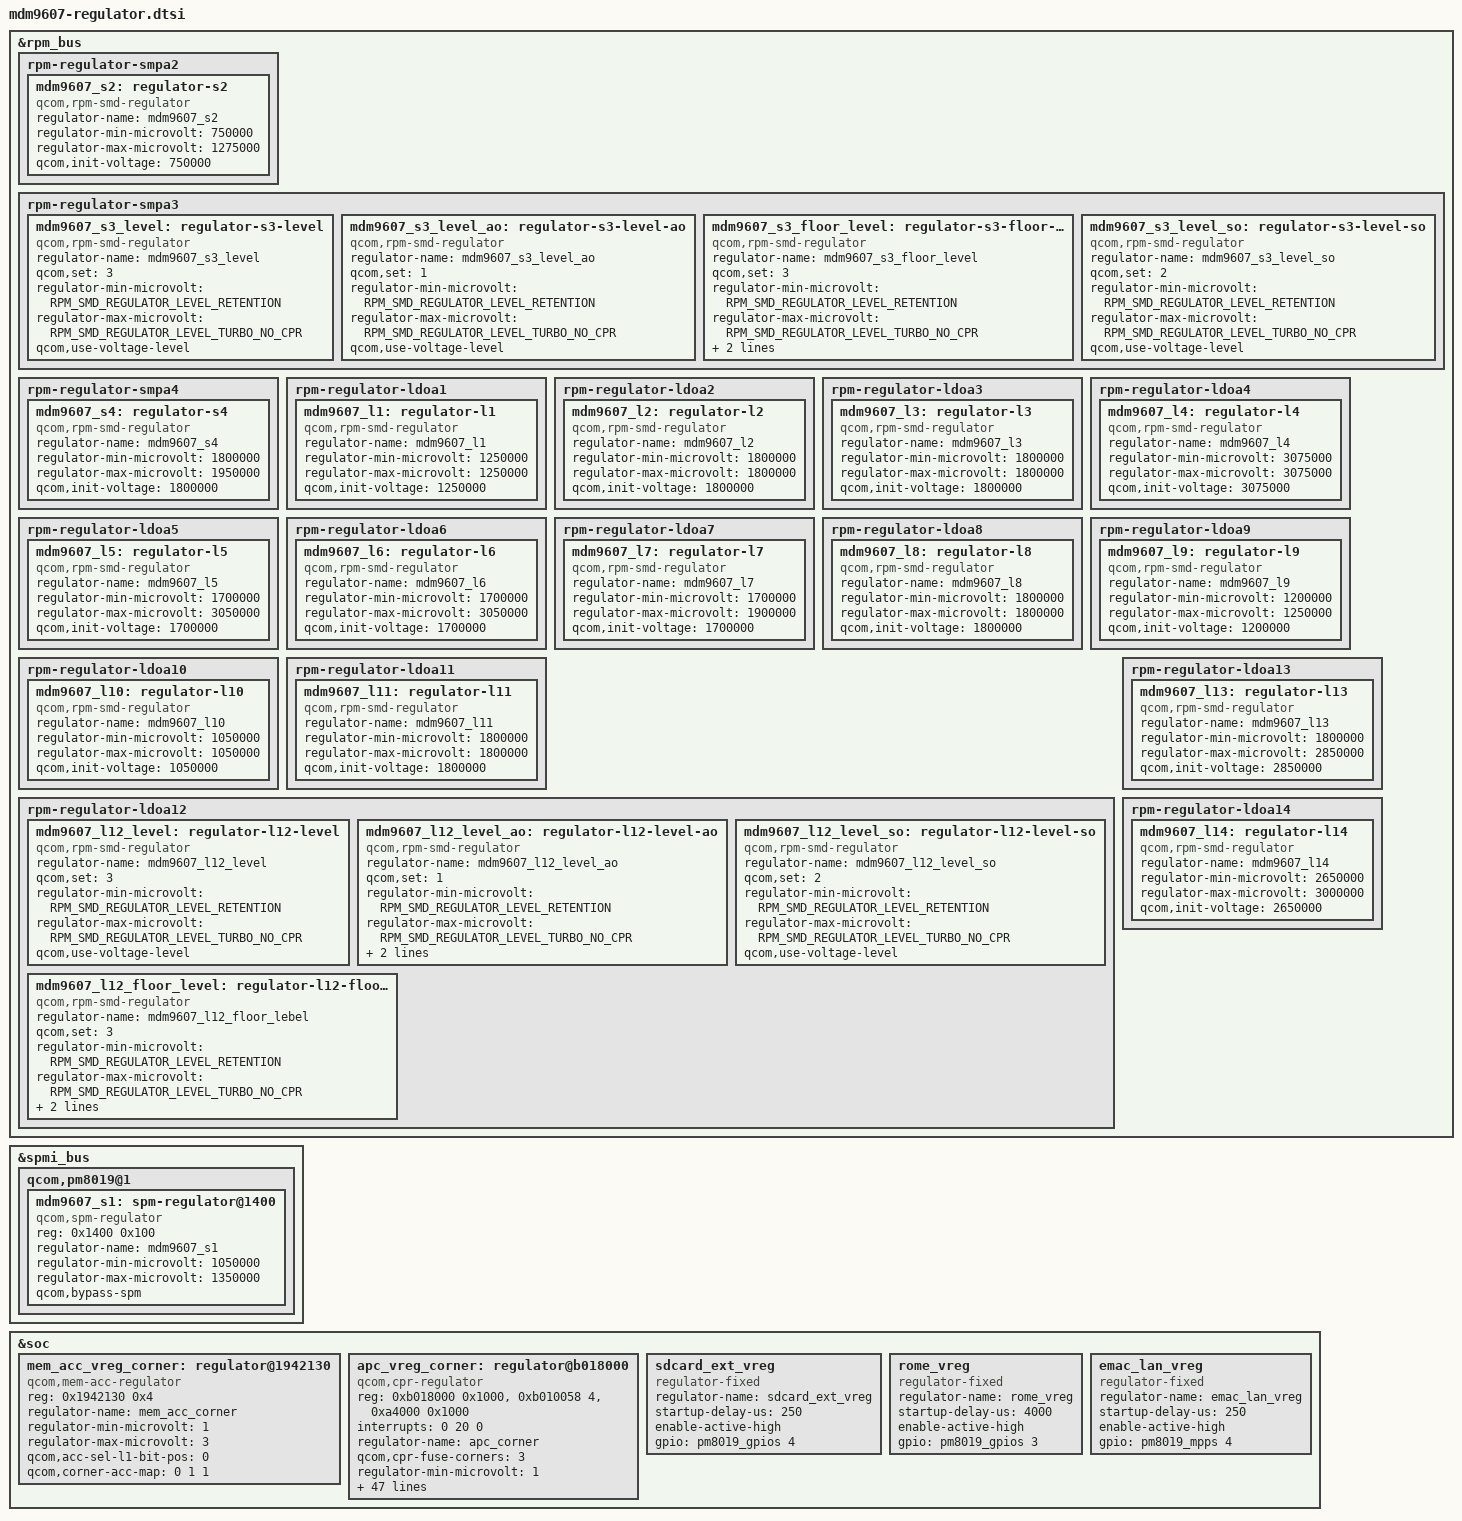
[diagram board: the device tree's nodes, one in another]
/* Copyright (c) 2015-2017, The Linux Foundation. All rights reserved.
 *
 * This program is free software; you can redistribute it and/or modify
 * it under the terms of the GNU General Public License version 2 and
 * only version 2 as published by the Free Software Foundation.
 *
 * This program is distributed in the hope that it will be useful,
 * but WITHOUT ANY WARRANTY; without even the implied warranty of
 * MERCHANTABILITY or FITNESS FOR A PARTICULAR PURPOSE.  See the
 * GNU General Public License for more details.
 */

&rpm_bus {
	rpm-regulator-smpa2 {
		status = "okay";
		mdm9607_s2: regulator-s2 {
			compatible = "qcom,rpm-smd-regulator";
			regulator-name = "mdm9607_s2";
			regulator-min-microvolt = <750000>;
			regulator-max-microvolt = <1275000>;
			qcom,init-voltage = <750000>;
			status = "okay";
		};
	};

	/* CX supply */
	rpm-regulator-smpa3 {
		status = "okay";
		mdm9607_s3_level: regulator-s3-level {
			compatible = "qcom,rpm-smd-regulator";
			regulator-name = "mdm9607_s3_level";
			qcom,set = <3>;
			regulator-min-microvolt =
					<RPM_SMD_REGULATOR_LEVEL_RETENTION>;
			regulator-max-microvolt =
					<RPM_SMD_REGULATOR_LEVEL_TURBO_NO_CPR>;
			qcom,use-voltage-level;
		};

		mdm9607_s3_level_ao: regulator-s3-level-ao {
			compatible = "qcom,rpm-smd-regulator";
			regulator-name = "mdm9607_s3_level_ao";
			qcom,set = <1>;
			regulator-min-microvolt =
					<RPM_SMD_REGULATOR_LEVEL_RETENTION>;
			regulator-max-microvolt =
					<RPM_SMD_REGULATOR_LEVEL_TURBO_NO_CPR>;
			qcom,use-voltage-level;
		};

		mdm9607_s3_floor_level: regulator-s3-floor-level {
			compatible = "qcom,rpm-smd-regulator";
			regulator-name = "mdm9607_s3_floor_level";
			qcom,set = <3>;
			regulator-min-microvolt =
					<RPM_SMD_REGULATOR_LEVEL_RETENTION>;
			regulator-max-microvolt =
					<RPM_SMD_REGULATOR_LEVEL_TURBO_NO_CPR>;
			qcom,use-voltage-floor-level;
			qcom,always-send-voltage;
		};

		mdm9607_s3_level_so: regulator-s3-level-so {
			compatible = "qcom,rpm-smd-regulator";
			regulator-name = "mdm9607_s3_level_so";
			qcom,set = <2>;
			regulator-min-microvolt =
					<RPM_SMD_REGULATOR_LEVEL_RETENTION>;
			regulator-max-microvolt =
					<RPM_SMD_REGULATOR_LEVEL_TURBO_NO_CPR>;
			qcom,use-voltage-level;
		};
	};

	rpm-regulator-smpa4 {
		status = "okay";
		mdm9607_s4: regulator-s4 {
			compatible = "qcom,rpm-smd-regulator";
			regulator-name = "mdm9607_s4";
			regulator-min-microvolt = <1800000>;
			regulator-max-microvolt = <1950000>;
			qcom,init-voltage = <1800000>;
			status = "okay";
		};
	};

	rpm-regulator-ldoa1 {
		status = "okay";
		mdm9607_l1: regulator-l1 {
			compatible = "qcom,rpm-smd-regulator";
			regulator-name = "mdm9607_l1";
			regulator-min-microvolt = <1250000>;
			regulator-max-microvolt = <1250000>;
			qcom,init-voltage = <1250000>;
			status = "okay";
		};
	};

	rpm-regulator-ldoa2 {
		status = "okay";
		mdm9607_l2: regulator-l2 {
			compatible = "qcom,rpm-smd-regulator";
			regulator-name = "mdm9607_l2";
			regulator-min-microvolt = <1800000>;
			regulator-max-microvolt = <1800000>;
			qcom,init-voltage = <1800000>;
			status = "okay";
		};
	};

	rpm-regulator-ldoa3 {
		status = "okay";
		mdm9607_l3: regulator-l3 {
			compatible = "qcom,rpm-smd-regulator";
			regulator-name = "mdm9607_l3";
			regulator-min-microvolt = <1800000>;
			regulator-max-microvolt = <1800000>;
			qcom,init-voltage = <1800000>;
			status = "okay";
		};
	};

	rpm-regulator-ldoa4 {
		status = "okay";
		mdm9607_l4: regulator-l4 {
			compatible = "qcom,rpm-smd-regulator";
			regulator-name = "mdm9607_l4";
			regulator-min-microvolt = <3075000>;
			regulator-max-microvolt = <3075000>;
			qcom,init-voltage = <3075000>;
			status = "okay";
		};
	};

	rpm-regulator-ldoa5 {
		status = "okay";
		mdm9607_l5: regulator-l5 {
			compatible = "qcom,rpm-smd-regulator";
			regulator-name = "mdm9607_l5";
			regulator-min-microvolt = <1700000>;
			regulator-max-microvolt = <3050000>;
			qcom,init-voltage = <1700000>;
			status = "okay";
		};
	};

	rpm-regulator-ldoa6 {
		status = "okay";
		mdm9607_l6: regulator-l6 {
			compatible = "qcom,rpm-smd-regulator";
			regulator-name = "mdm9607_l6";
			regulator-min-microvolt = <1700000>;
			regulator-max-microvolt = <3050000>;
			qcom,init-voltage = <1700000>;
			status = "okay";
		};
	};

	rpm-regulator-ldoa7 {
		status = "okay";
		mdm9607_l7: regulator-l7 {
			compatible = "qcom,rpm-smd-regulator";
			regulator-name = "mdm9607_l7";
			regulator-min-microvolt = <1700000>;
			regulator-max-microvolt = <1900000>;
			qcom,init-voltage = <1700000>;
			status = "okay";
		};
	};

	rpm-regulator-ldoa8 {
		status = "okay";
		mdm9607_l8: regulator-l8 {
			compatible = "qcom,rpm-smd-regulator";
			regulator-name = "mdm9607_l8";
			regulator-min-microvolt = <1800000>;
			regulator-max-microvolt = <1800000>;
			qcom,init-voltage = <1800000>;
			status = "okay";
		};
	};

	rpm-regulator-ldoa9 {
		status = "okay";
		mdm9607_l9: regulator-l9 {
			compatible = "qcom,rpm-smd-regulator";
			regulator-name = "mdm9607_l9";
			regulator-min-microvolt = <1200000>;
			regulator-max-microvolt = <1250000>;
			qcom,init-voltage = <1200000>;
			status = "okay";
		};
	};

	rpm-regulator-ldoa10 {
		status = "okay";
		mdm9607_l10: regulator-l10 {
			compatible = "qcom,rpm-smd-regulator";
			regulator-name = "mdm9607_l10";
			regulator-min-microvolt = <1050000>;
			regulator-max-microvolt = <1050000>;
			qcom,init-voltage = <1050000>;
			status = "okay";
		};
	};

	rpm-regulator-ldoa11 {
		status = "okay";
		mdm9607_l11: regulator-l11 {
			compatible = "qcom,rpm-smd-regulator";
			regulator-name = "mdm9607_l11";
			regulator-min-microvolt = <1800000>;
			regulator-max-microvolt = <1800000>;
			qcom,init-voltage = <1800000>;
			status = "okay";
		};
	};

	/* MX supply */
	rpm-regulator-ldoa12 {
		status = "okay";
		mdm9607_l12_level: regulator-l12-level {
			compatible = "qcom,rpm-smd-regulator";
			regulator-name = "mdm9607_l12_level";
			qcom,set = <3>;
			regulator-min-microvolt =
					<RPM_SMD_REGULATOR_LEVEL_RETENTION>;
			regulator-max-microvolt =
					<RPM_SMD_REGULATOR_LEVEL_TURBO_NO_CPR>;
			qcom,use-voltage-level;
		};

		mdm9607_l12_level_ao: regulator-l12-level-ao {
			compatible = "qcom,rpm-smd-regulator";
			regulator-name = "mdm9607_l12_level_ao";
			qcom,set = <1>;
			regulator-min-microvolt =
					<RPM_SMD_REGULATOR_LEVEL_RETENTION>;
			regulator-max-microvolt =
					<RPM_SMD_REGULATOR_LEVEL_TURBO_NO_CPR>;
			qcom,use-voltage-level;
			qcom,always-send-voltage;
		};

		mdm9607_l12_level_so: regulator-l12-level-so {
			compatible = "qcom,rpm-smd-regulator";
			regulator-name = "mdm9607_l12_level_so";
			qcom,set = <2>;
			regulator-min-microvolt =
					<RPM_SMD_REGULATOR_LEVEL_RETENTION>;
			regulator-max-microvolt =
					<RPM_SMD_REGULATOR_LEVEL_TURBO_NO_CPR>;
			qcom,use-voltage-level;
		};

		mdm9607_l12_floor_level: regulator-l12-floor-level {
			compatible = "qcom,rpm-smd-regulator";
			regulator-name = "mdm9607_l12_floor_lebel";
			qcom,set = <3>;
			regulator-min-microvolt =
					<RPM_SMD_REGULATOR_LEVEL_RETENTION>;
			regulator-max-microvolt =
					<RPM_SMD_REGULATOR_LEVEL_TURBO_NO_CPR>;
			qcom,use-voltage-floor-level;
			qcom,always-send-voltage;
		};
	};

	rpm-regulator-ldoa13 {
		status = "okay";
		mdm9607_l13: regulator-l13 {
			compatible = "qcom,rpm-smd-regulator";
			regulator-name = "mdm9607_l13";
			regulator-min-microvolt = <1800000>;
			regulator-max-microvolt = <2850000>;
			qcom,init-voltage = <2850000>;
			status = "okay";
		};
	};

	rpm-regulator-ldoa14 {
		status = "okay";
		mdm9607_l14: regulator-l14 {
			compatible = "qcom,rpm-smd-regulator";
			regulator-name = "mdm9607_l14";
			regulator-min-microvolt = <2650000>;
			regulator-max-microvolt = <3000000>;
			qcom,init-voltage = <2650000>;
			status = "okay";
		};
	};
};

&spmi_bus {
	qcom,pm8019@1 {
		/* APC supply */
		mdm9607_s1: spm-regulator@1400 {
			compatible = "qcom,spm-regulator";
			reg = <0x1400 0x100>;
			regulator-name = "mdm9607_s1";
			regulator-min-microvolt = <1050000>;
			regulator-max-microvolt = <1350000>;
			qcom,bypass-spm; /* TODO: Remove once SPM is up */
		};
	};
};

&soc {
	mem_acc_vreg_corner: regulator@1942130 {
		compatible = "qcom,mem-acc-regulator";
		reg = <0x1942130 0x4>;
		reg-names = "acc-sel-l1";
		regulator-name = "mem_acc_corner";
		regulator-min-microvolt = <1>;
		regulator-max-microvolt = <3>;

		qcom,acc-sel-l1-bit-pos = <0>;
		qcom,corner-acc-map = <0 1 1>;
	};

	apc_vreg_corner: regulator@b018000 {
		compatible = "qcom,cpr-regulator";
		reg = <0xb018000 0x1000>, <0xb010058 4>, <0xa4000 0x1000>;
		reg-names = "rbcpr", "rbcpr_clk", "efuse_addr";
		interrupts = <0 20 0>;
		regulator-name = "apc_corner";
		qcom,cpr-fuse-corners = <3>;
		regulator-min-microvolt = <1>;
		regulator-max-microvolt = <7>;

		qcom,cpr-voltage-ceiling = <1050000 1225000 1350000>;
		qcom,cpr-voltage-floor = <1050000 1050000 1150000>;
		vdd-apc-supply = <&mdm9607_s1>;

		vdd-mx-supply = <&mdm9607_l12_level_ao>;
		qcom,vdd-mx-vmin-method = <4>;
		qcom,vdd-mx-corner-map = < RPM_SMD_REGULATOR_LEVEL_SVS
					   RPM_SMD_REGULATOR_LEVEL_NOM
					   RPM_SMD_REGULATOR_LEVEL_TURBO>;
		qcom,vdd-mx-vmax = <RPM_SMD_REGULATOR_LEVEL_TURBO_NO_CPR>;

		mem-acc-supply = <&mem_acc_vreg_corner>;

		qcom,cpr-ref-clk = <19200>;
		qcom,cpr-timer-delay = <5000>;
		qcom,cpr-timer-cons-up = <0>;
		qcom,cpr-timer-cons-down = <2>;
		qcom,cpr-irq-line = <0>;
		qcom,cpr-step-quotient = <22 0 24 0 0 0 0 0>;
		qcom,cpr-up-threshold = <2>;
		qcom,cpr-down-threshold = <3>;
		qcom,cpr-idle-clocks = <15>;
		qcom,cpr-gcnt-time = <1>;
		qcom,vdd-apc-step-up-limit = <1>;
		qcom,vdd-apc-step-down-limit = <1>;
		qcom,cpr-apc-volt-step = <12500>;

		qcom,cpr-fuse-row = <65 0>;
		qcom,cpr-fuse-target-quot = <24 12 0>;
		qcom,cpr-fuse-ro-sel = <42 39 36>;
		qcom,cpr-fuse-bp-cpr-disable = <54>;
		qcom,cpr-fuse-init-voltage =
					<66 6 6 0>,
					<66 0 6 0>,
					<65 45 6 0>;
		qcom,cpr-fuse-revision = <65 51 3 0>;
		qcom,cpr-init-voltage-ref = <1050000 1225000 1350000>;
		qcom,cpr-init-voltage-step = <10000>;
		qcom,cpr-corner-map = <1 2 3 3 3 3 3>;
		qcom,cpr-init-voltage-as-ceiling;
		qcom,cpr-corner-frequency-map =
					<1 400000000>,
					<2 800000000>,
					<3 998400000>,
					<4 1094400000>,
					<5 1190400000>,
					<6 1248000000>,
					<7 1305600000>;
		qcom,speed-bin-fuse-sel = <37 34 3 0>;
		qcom,cpr-speed-bin-max-corners =
					<0 0 1 2 7>;
		qcom,cpr-quot-adjust-scaling-factor-max = <1400>;
		qcom,disable-closed-loop-in-pc;
		qcom,cpr-cpus = <&CPU0>;
		qcom,cpr-enable;
	};

/* Miscellaneous regulators */
	sdcard_ext_vreg: sdcard_ext_vreg {
		compatible = "regulator-fixed";
		regulator-name = "sdcard_ext_vreg";
		startup-delay-us = <250>;
		enable-active-high;
		gpio = <&pm8019_gpios 4 0>;
	};

	/* Rome 3.3V supply */
	rome_vreg: rome_vreg {
		compatible = "regulator-fixed";
		regulator-name = "rome_vreg";
		startup-delay-us = <4000>;
		enable-active-high;
		gpio = <&pm8019_gpios 3 0>;
	};

	emac_lan_vreg: emac_lan_vreg {
		compatible = "regulator-fixed";
		regulator-name = "emac_lan_vreg";
		startup-delay-us = <250>;
		enable-active-high;
		gpio = <&pm8019_mpps 4 0>;
	};
};
